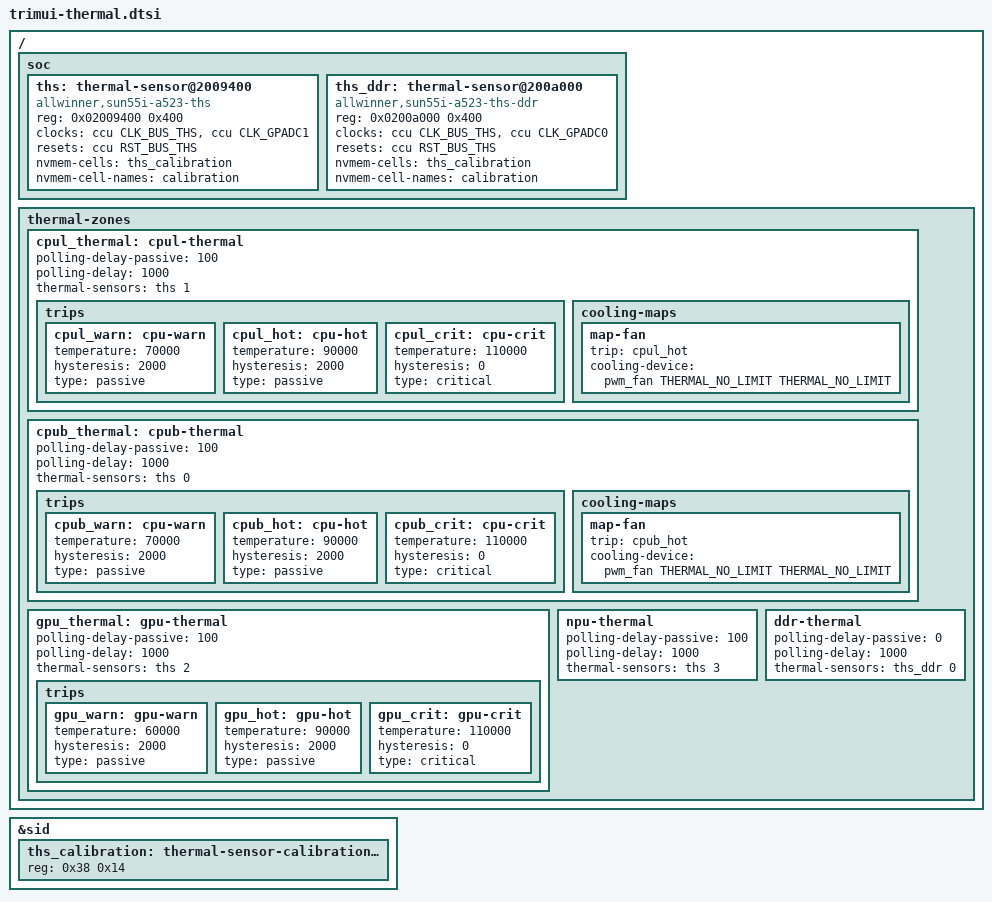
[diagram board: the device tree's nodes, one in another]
// SPDX-License-Identifier: (GPL-2.0-only OR MIT)
// Copyright (C) 2026 Midgy BALON
/*
 * A523 thermal — THS sensors + thermal-zones + active pwm-fan cooling.
 *
 * The THS *driver* is adopted from ut-slayer (kernel/patches/0021-0023,
 * allwinner,sun55i-a523-ths + -ths-ddr). Their SoC-dtsi patch (0087/0089)
 * doesn't apply to v7.2's shifted context, so we express the same nodes here
 * as board-level additions (THS via /soc, the calibration cell via &sid, the
 * zones + our pwm-fan cooling-maps). Node/zone/trip values are transcribed from
 * ut-slayer (BSP-derived); trip temps VERIFY/tune on hardware.
 *
 * Enable by `#include`ing this from the board DTS (needs the 0021-0023 patches +
 * CONFIG_SUN8I_THERMAL + CONFIG_THERMAL_GOV_*). The fan map hooks the pwm-fan on
 * the cpu-hot (90 C) trips; with the CPUs' dynamic-power-coefficient (see
 * trimui-cpu-opp.dtsi) IPA can also throttle cpufreq. See docs/THERMAL-DVFS-NOTES.md.
 */

#include <dt-bindings/thermal/thermal.h>

/* THS calibration lives in the SID efuse (0x38, 20 bytes). */
&sid {
	#address-cells = <1>;
	#size-cells = <1>;

	ths_calibration: thermal-sensor-calibration@38 {
		reg = <0x38 0x14>;
	};
};

/ {
	soc {
		ths: thermal-sensor@2009400 {
			compatible = "allwinner,sun55i-a523-ths";
			reg = <0x02009400 0x400>;
			clocks = <&ccu CLK_BUS_THS>, <&ccu CLK_GPADC1>;
			clock-names = "bus", "mod";
			resets = <&ccu RST_BUS_THS>;
			nvmem-cells = <&ths_calibration>;
			nvmem-cell-names = "calibration";
			#thermal-sensor-cells = <1>;
		};

		ths_ddr: thermal-sensor@200a000 {
			compatible = "allwinner,sun55i-a523-ths-ddr";
			reg = <0x0200a000 0x400>;
			clocks = <&ccu CLK_BUS_THS>, <&ccu CLK_GPADC0>;
			clock-names = "bus", "mod";
			resets = <&ccu RST_BUS_THS>;
			nvmem-cells = <&ths_calibration>;
			nvmem-cell-names = "calibration";
			#thermal-sensor-cells = <1>;
		};
	};

	thermal-zones {
		cpul_thermal: cpul-thermal {
			polling-delay-passive = <100>;
			polling-delay = <1000>;
			thermal-sensors = <&ths 1>;	/* little cluster */

			trips {
				cpul_warn: cpu-warn { temperature = <70000>; hysteresis = <2000>; type = "passive"; };
				cpul_hot: cpu-hot { temperature = <90000>; hysteresis = <2000>; type = "passive"; };
				cpul_crit: cpu-crit { temperature = <110000>; hysteresis = <0>; type = "critical"; };
			};

			cooling-maps {
				map-fan {
					trip = <&cpul_hot>;
					cooling-device = <&pwm_fan THERMAL_NO_LIMIT THERMAL_NO_LIMIT>;
				};
			};
		};

		cpub_thermal: cpub-thermal {
			polling-delay-passive = <100>;
			polling-delay = <1000>;
			thermal-sensors = <&ths 0>;	/* big cluster (the hot one) */

			trips {
				cpub_warn: cpu-warn { temperature = <70000>; hysteresis = <2000>; type = "passive"; };
				cpub_hot: cpu-hot { temperature = <90000>; hysteresis = <2000>; type = "passive"; };
				cpub_crit: cpu-crit { temperature = <110000>; hysteresis = <0>; type = "critical"; };
			};

			cooling-maps {
				map-fan {
					trip = <&cpub_hot>;
					cooling-device = <&pwm_fan THERMAL_NO_LIMIT THERMAL_NO_LIMIT>;
				};
			};
		};

		gpu_thermal: gpu-thermal {
			polling-delay-passive = <100>;
			polling-delay = <1000>;
			thermal-sensors = <&ths 2>;

			trips {
				gpu_warn: gpu-warn { temperature = <60000>; hysteresis = <2000>; type = "passive"; };
				gpu_hot: gpu-hot { temperature = <90000>; hysteresis = <2000>; type = "passive"; };
				gpu_crit: gpu-crit { temperature = <110000>; hysteresis = <0>; type = "critical"; };
			};
		};

		npu-thermal {
			polling-delay-passive = <100>;
			polling-delay = <1000>;
			thermal-sensors = <&ths 3>;
		};

		ddr-thermal {
			polling-delay-passive = <0>;
			polling-delay = <1000>;
			thermal-sensors = <&ths_ddr 0>;
		};
	};
};
